NS_ :

BS_:

BU_:

BO_ 200 Test: 1 Vector__XXX
 SG_ Test_Message : 0|8@1+ (1,0) [0|0] "" Vector__XXX

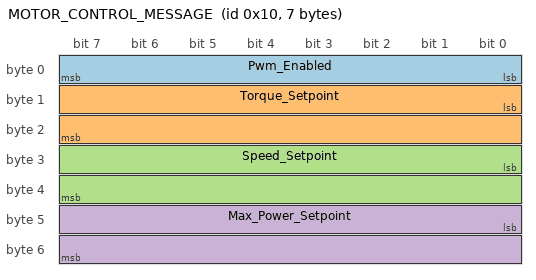
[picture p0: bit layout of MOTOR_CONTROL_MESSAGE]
BO_ 16 MOTOR_CONTROL_MESSAGE: 7 Vector__XXX
 SG_ Pwm_Enabled : 0|8@1+ (1,0) [0|0] "" Vector__XXX
 SG_ Torque_Setpoint : 8|16@1+ (1,0) [0|0] "" Vector__XXX
 SG_ Speed_Setpoint : 24|16@1+ (1,0) [0|0] "" Vector__XXX
 SG_ Max_Power_Setpoint : 40|16@1+ (1,0) [0|0] "" Vector__XXX

BO_ 17 Front_Node: 4 Vector__XXX
 SG_ Apps_value : 0|32@1+ (1,0) [0|0] "per" Vector__XXX

SIG_VALTYPE_ 17 Apps_value : 1;
